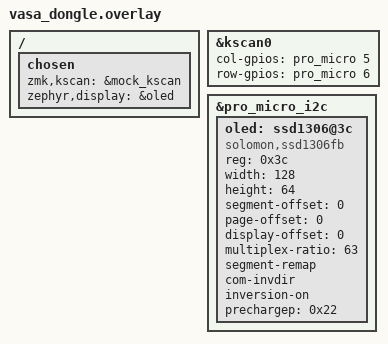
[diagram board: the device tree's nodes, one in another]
#include "vasa.dtsi"
&kscan0 {
	col-gpios
	= <&pro_micro 5 (GPIO_ACTIVE_HIGH)>
	;
    row-gpios
	= <&pro_micro 6 (GPIO_ACTIVE_HIGH | GPIO_PULL_DOWN)>
    ;
};
/ {
    chosen {
        zmk,kscan = &mock_kscan;
        zephyr,display = &oled;
    };

};

/delete-node/ &default_kscan;   // only required if the dongle uses a 
                                // different board than the peripherals

&pro_micro_i2c {
    status = "okay";
    
    oled: ssd1306@3c {
        compatible = "solomon,ssd1306fb";
        reg = <0x3c>;
        width = <128>;
        height = <64>;
        segment-offset = <0>;
        page-offset = <0>;
        display-offset = <0>;
        multiplex-ratio = <63>;
        segment-remap;
        com-invdir;
        inversion-on;
        prechargep = <0x22>;
    };
};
